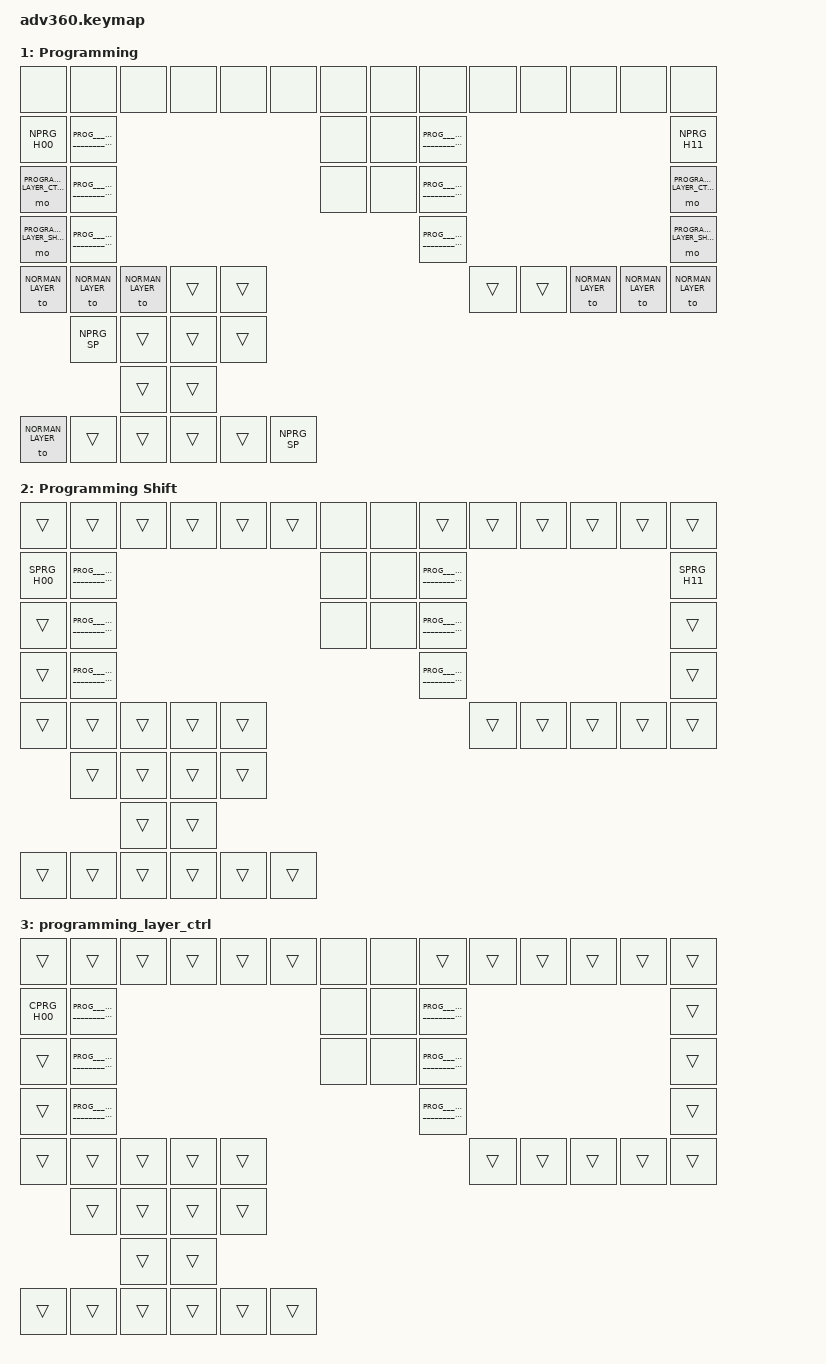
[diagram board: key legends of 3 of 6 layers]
#include <behaviors.dtsi>
#include <dt-bindings/zmk/keys.h>
#include <dt-bindings/zmk/bt.h>
#include <dt-bindings/zmk/rgb.h>
#include <dt-bindings/zmk/stp.h>
#include <dt-bindings/zmk/backlight.h>
#include <dt-bindings/zmk/pointing.h>

#define NORMAN_LAYER 0
#define PROGRAMMING_LAYER 1
#define PROGRAMMING_LAYER_SHIFT 2
#define PROGRAMMING_LAYER_CTRL 3
#define LOWER_LAYER 4
#define MOD_LAYER 5
#define GUI_LAYER 1

#define MO_MOD &mo MOD_LAYER

#define MO_LOWER &mo LOWER_LAYER
#define TOG_LOWER &tog LOWER_LAYER

// sticky-layer
&sl { release-after-ms = <999999>; };

// FIXME: shift+NPRG_CM should insert <, not activate the layer
#define NPRG_CM &sl PROGRAMMING_LAYER
#define MO_SPRG &mo PROGRAMMING_LAYER_SHIFT
#define MO_CPRG &mo PROGRAMMING_LAYER_CTRL
#define STCH_EX &to NORMAN_LAYER

#define ____________________NUMBERS__L___________________  &kp N1    &kp N2    &kp N3    &kp N4    &kp N5
#define ____________________NUMBERS__R___________________  &kp N6    &kp N7    &kp N8    &kp N9    &kp N0
#define ____________________QWERTY__L1___________________  &kp Q     &kp W     &kp E     &kp R     &kp T
#define ____________________QWERTY__L2___________________  &kp A     &kp S     &kp D     &kp F     &kp G
#define ____________________QWERTY__L3___________________  &kp Z     &kp X     &kp C     &kp V     &kp B
#define ____________________QWERTY__R1___________________  &kp Y     &kp U     &kp I     &kp O     &kp P
#define ____________________QWERTY__R2___________________  &kp H     &kp J     &kp K     &kp L     &kp SEMI
#define ____________________QWERTY__R3___________________  &kp N     &kp M     &kp COMMA &kp DOT   &kp FSLH
#define ____________________NORMAN__L1___________________  &kp Q     &kp W     &kp D     &kp F     &kp K
#define ____________________NORMAN__L2___________________  &kp A     &kp S     &kp E     &kp T     &kp G
#define ____________________NORMAN__L3___________________  &kp Z     &kp X     &kp C     &kp V     &kp B
#define ____________________NORMAN__R1___________________  &kp J     &kp U     &kp R     &kp L     &kp ESC
#define ____________________NORMAN__R2___________________  &kp Y     &kp N     &kp I     &kp O     &kp H
#define ____________________NORMAN__R3___________________  &kp P     &kp M     NPRG_CM   &kp DOT   &kp FSLH

#define ______________________________LOWER___L1___________________  &none     &kp LEFT     &kp DOWN     &kp UP       &kp RIGHT     &kp Z
#define ____________________LOWER___R1__________________________     &kp J     &kp HOME     &kp PGDN     &kp PGUP     &kp END       &kp DEL
#define ______________________________LOWER___L2___________________  &none     &kp HOME     &kp PGUP     &kp PGDN     &kp END       &none
#define ____________________LOWER___R2__________________________     &kp Z     &kp LEFT     &kp DOWN     &kp UP       &kp RIGHT     &none
#define ______________________________LOWER___L3___________________  &kp LSHFT &kp LG(LEFT) &kp LG(UP)   &kp LG(DOWN) &kp LG(RIGHT) &none
#define ____________________LOWER___R3__________________________     &kp P     &kp LA(LEFT) &kp LA(DOWN) &kp LA(UP)   &kp LA(RIGHT) &kp RSHFT

// https://github.com/rastasheep/zmk-config/commit/b8607d4beb15a29671cf7921a1fe5060a7740c6b
#define HYP LS(LC(LA(LGUI)))
#define HYPER(key) LS(LC(LA(LG(key))))

// GUI_L,   HYPER_L, KC_LALT, KC_LGUI,                   KC_RGUI, KC_RALT, HYPER_R, GUI_R,
// FIXME: use layer-tap &lt for this:
#define GUI_L &kp LBKT
// #define GUI_L &mt &mo GUI_LAYER LBKT
#define GUI_R &kp RBKT
// #define GUI_R &mt &mo GUI_LAYER RBKT
#define HYPER_L &mt HYP RBKT
#define HYPER_R &mt HYP LBKT

#define CTL_ESC &mt LCTRL ESC
#define CTL_ENT &mt RCTRL ENTER

// presumes Ctrl-E will go to end of line
#define GEND_LINE &kp LC(E)

// RGB LEDs: on top of the thumb clusters
#define RGBLED_TG &rgb_ug RGB_MEFS_CMD 5
#define BOOTLOADR &bootloader
#define BT_SEL_0  &bt BT_SEL 0
#define BT_SEL_1  &bt BT_SEL 1
#define BT_SEL_2  &bt BT_SEL 2
#define BT_SEL_3  &bt BT_SEL 3
#define BT_SEL_4  &bt BT_SEL 4
#define BT_CLR___ &bt BT_CLR

#define BL_INC___ &bl BL_INC
#define BL_DEC___ &bl BL_DEC
#define BL_TOG___ &bl BL_TOG
#define RGB_TOG__ &rgb_ug RGB_TOG

/ {
  behaviors {
    #include "macros.dtsi"
      #include "version.dtsi"

    ZMK_MACRO(NPRG_SP, bindings = <&kp COMMA  &kp SPACE    STCH_EX>;)

// use Mod-Morph to combine these to a single layer?  https://zmk.dev/docs/behaviors/mod-morph
//
//↘↩ │  %  │  &  │  ?  │  +  │  @     $  │  _  │  [  │  ]  │  !  │ ↘␣{↩
//─────┼─────┼─────┼─────┼─────┼───     ───┼─────┼─────┼─────┼─────┼─────
//     │  /  │  (  │  =  │  ;  │  {     }  │  :  │  *  │  )  │  -  │
//─────┼─────┼─────┼─────┼─────┼───     ───┼─────┼─────┼─────┼─────┼─────
//     │  ~  │  `  │  ^  │  "  │  |     \  │  ,  │  #  │  '  │     │
#define ____________________PROG____L1___________________  &kp PRCNT &kp AMPS  &kp QMARK &kp PLUS  &kp AT
#define ____________________PROG____L2___________________  &kp FSLH  &kp LPAR  &kp EQUAL &kp SEMI  &kp LBRC
#define ____________________PROG____L3___________________  &kp TILDE &kp GRAVE &kp CARET &kp DQT   &kp PIPE
#define ____________________PROG____R1___________________  &kp DLLR  &kp UNDER &kp LBKT  &kp RBKT  &kp EXCL
#define ____________________PROG____R2___________________  &kp RBRC  &kp COLON &kp STAR  &kp RPAR  &kp MINUS
#define ____________________PROG____R3___________________  &kp BSLH  &kp COMMA &kp HASH  &kp SQT   &none

    ZMK_MACRO(NPRG_H00, bindings = <GEND_LINE &kp ENTER STCH_EX>;)
    ZMK_MACRO(NPRG_H11, bindings = <GEND_LINE &kp SPACE &kp LBRC  &kp ENTER STCH_EX>;)

//          1     2     3     4     5      6    7     8     9     10
// H ↘;↩│     │ &&  │     │ +=  │ @q        │     │ []  │ ->  │ !=  │ ↘␣{
//   ─────┼─────┼─────┼─────┼─────┼───     ───┼─────┼─────┼─────┼─────┼─────
// M      │ /=  │ ()  │ ==  │     │ {}        │ ::  │     │     │ -=  │
//   ─────┼─────┼─────┼─────┼─────┼───     ───┼─────┼─────┼─────┼─────┼─────
// L      │     │     │     │     │ ||        │     │ <=  │ >=  │     │
#define ____________________PROG___SL1___________________  &none     &SPRG_H02 &none     &SPRG_H04 &SPRG_H05
#define ____________________PROG___SL2___________________  &SPRG_M01 &SPRG_M02 &SPRG_M03 &none     &SPRG_M05
#define ____________________PROG___SL3___________________  &none     &none     &none     &none     &SPRG_L05
#define ____________________PROG___SR1___________________  &none     &none     &SPRG_H08 &SPRG_H09 &SPRG_H10
#define ____________________PROG___SR2___________________  &none     &SPRG_M07 &none     &none     &SPRG_M10
#define ____________________PROG___SR3___________________  &none     &none     &SPRG_L08 &SPRG_L09 &none

    ZMK_MACRO(SPRG_H00, bindings = <GEND_LINE &kp SEMI  &kp ENTER STCH_EX>;)
    ZMK_MACRO(SPRG_H11, bindings = <GEND_LINE &kp SPACE &kp LBRC  STCH_EX>;)

    ZMK_MACRO(SPRG_H02, bindings = <&kp AMPS  &kp AMPS    STCH_EX>;)
    ZMK_MACRO(SPRG_H04, bindings = <&kp PLUS  &kp EQUAL   STCH_EX>;)
    ZMK_MACRO(SPRG_H05, bindings = <&kp AT    &kp Q       STCH_EX>;)
    ZMK_MACRO(SPRG_H08, bindings = <&kp LBKT  &kp RBKT    STCH_EX>;)
    ZMK_MACRO(SPRG_H09, bindings = <&kp MINUS &kp GT      STCH_EX>;)
    ZMK_MACRO(SPRG_H10, bindings = <&kp EXCL  &kp EQUAL   STCH_EX>;)

    ZMK_MACRO(SPRG_M01, bindings = <&kp FSLH  &kp EQUAL   STCH_EX>;)
    ZMK_MACRO(SPRG_M02, bindings = <&kp LPAR  &kp RPAR    STCH_EX>;)
    ZMK_MACRO(SPRG_M03, bindings = <&kp EQUAL &kp EQUAL   STCH_EX>;)
    ZMK_MACRO(SPRG_M05, bindings = <&kp LBRC  &kp RBRC    STCH_EX>;)
    ZMK_MACRO(SPRG_M07, bindings = <&kp COLON &kp COLON   STCH_EX>;)
    ZMK_MACRO(SPRG_M10, bindings = <&kp MINUS &kp EQUAL   STCH_EX>;)

    ZMK_MACRO(SPRG_L05, bindings = <&kp PIPE  &kp PIPE    STCH_EX>;)
    ZMK_MACRO(SPRG_L08, bindings = <&kp LT    &kp EQUAL   STCH_EX>;)
    ZMK_MACRO(SPRG_L09, bindings = <&kp GT    &kp EQUAL   STCH_EX>;)

//          1     2     3     4     5      6    7     8     9     10
// H ↘:↩│     │     │     │ ++  │ @@        │     │     │     │     │
//   ─────┼─────┼─────┼─────┼─────┼───     ───┼─────┼─────┼─────┼─────┼─────
// M      │     │     │ =>  │     │           │ :=  │     │     │ --  │
//   ─────┼─────┼─────┼─────┼─────┼───     ───┼─────┼─────┼─────┼─────┼─────
// L      │     │     │     │     │           │     │     │     │     │
#define ____________________PROG___CL1___________________  &none     &none     &none     &CPRG_H04 &CPRG_H05
#define ____________________PROG___CL2___________________  &none     &none     &CPRG_M03 &none     &none
#define ____________________PROG___CL3___________________  &none     &none     &none     &none     &none
#define ____________________PROG___CR1___________________  &none     &none     &none     &none     &none
#define ____________________PROG___CR2___________________  &none     &CPRG_M07 &none     &none     &CPRG_M10
#define ____________________PROG___CR3___________________  &none     &none     &none     &none     &none

    ZMK_MACRO(CPRG_H00, bindings = <GEND_LINE &kp COLON &kp ENTER STCH_EX>;)

    ZMK_MACRO(CPRG_H04, bindings = <&kp PLUS  &kp PLUS    STCH_EX>;)
    ZMK_MACRO(CPRG_H05, bindings = <&kp AT    &kp AT      STCH_EX>;)

    ZMK_MACRO(CPRG_M03, bindings = <&kp EQUAL &kp GT      STCH_EX>;)
    ZMK_MACRO(CPRG_M07, bindings = <&kp COLON &kp EQUAL   STCH_EX>;)
    ZMK_MACRO(CPRG_M10, bindings = <&kp MINUS &kp MINUS   STCH_EX>;)

    hm: homerow_mods {
      compatible = "zmk,behavior-hold-tap";
      label = "HOMEROW_MODS";
      #binding-cells = <2>;
      tapping-term-ms = <200>;
      quick_tap_ms = <175>;
      flavor = "tap-preferred";
      bindings = <&kp>, <&kp>;
    };
  };

  keymap {
    compatible = "zmk,keymap";

    // 0
    default_layer {
      //_________ _________ _________ _________ _________ _________ _________   _________ _________ _________ _________ _________ _________ _________
      display-name = "Base";
      bindings = <
        &kp EQUAL ____________________NUMBERS__L___________________ MO_MOD      MO_MOD    ____________________NUMBERS__R___________________ &kp MINUS
        &kp TAB   ____________________NORMAN__L1___________________ &none       &none     ____________________NORMAN__R1___________________ &kp BSLH
        CTL_ESC   ____________________NORMAN__L2___________________ &none       &none     ____________________NORMAN__R2___________________ CTL_ENT
        &kp LSHFT ____________________NORMAN__L3___________________                       ____________________NORMAN__R3___________________ &kp RSHFT
        NPRG_CM   GUI_L     HYPER_L   &kp LALT  &kp LGUI                                            &kp RGUI  &kp RALT  HYPER_R   GUI_R     NPRG_CM

                  &kp SPACE &kp CAPS  &kp CAPS  &kp ESC
                            &none     &none
        MO_LOWER  &kp BSPC  &none     TOG_LOWER &kp ENTER &kp SPACE
      >;
    };
    // 1
    programming_layer {
      //_________ _________ _________ _________ _________ _________ _________   _________ _________ _________ _________ _________ _________ _________
      display-name = "Programming";
      bindings = <
        &none     &none     &none     &none     &none     &none     &none       &none     &none     &none      &none     &none     &none    &none
        &NPRG_H00 ____________________PROG____L1___________________ &none       &none     ____________________PROG____R1___________________ &NPRG_H11
        MO_CPRG   ____________________PROG____L2___________________ &none       &none     ____________________PROG____R2___________________ MO_CPRG
        MO_SPRG   ____________________PROG____L3___________________                       ____________________PROG____R3___________________ MO_SPRG
        STCH_EX   STCH_EX   STCH_EX   &trans    &trans                                              &trans     &trans    STCH_EX   STCH_EX  STCH_EX

                  &NPRG_SP  &trans    &trans    &trans
                            &trans    &trans
        STCH_EX   &trans    &trans    &trans    &trans   &NPRG_SP
      >;
    };
    // 2
    programming_layer_shift {
      //_________ _________ _________ _________ _________ _________ _________   _________ _________ _________ _________ _________ _________ _________
      display-name = "Programming Shift";
      bindings = <
        &trans    &trans    &trans    &trans    &trans    &trans    &none       &none     &trans    &trans    &trans    &trans    &trans    &trans
        &SPRG_H00 ____________________PROG___SL1___________________ &none       &none     ____________________PROG___SR1___________________ &SPRG_H11
        &trans    ____________________PROG___SL2___________________ &none       &none     ____________________PROG___SR2___________________ &trans
        &trans    ____________________PROG___SL3___________________                       ____________________PROG___SR3___________________ &trans
        &trans    &trans    &trans    &trans    &trans                                              &trans    &trans    &trans    &trans    &trans

                  &trans    &trans    &trans    &trans
                            &trans    &trans
        &trans    &trans    &trans    &trans    &trans    &trans
      >;
    };
    // 3
    programming_layer_ctrl {
      //_________ _________ _________ _________ _________ _________ _________   _________ _________ _________ _________ _________ _________ _________
      bindings = <
        &trans    &trans    &trans    &trans    &trans    &trans    &none       &none     &trans    &trans    &trans    &trans    &trans    &trans
        &CPRG_H00 ____________________PROG___CL1___________________ &none       &none     ____________________PROG___CR1___________________ &trans
        &trans    ____________________PROG___CL2___________________ &none       &none     ____________________PROG___CR2___________________ &trans
        &trans    ____________________PROG___CL3___________________                       ____________________PROG___CR3___________________ &trans
        &trans    &trans    &trans    &trans    &trans                                              &trans    &trans    &trans    &trans    &trans

                  &trans    &trans    &trans    &trans
                            &trans    &trans
        &trans    &trans    &trans    &trans    &trans    &trans
      >;
    };
    // 4
    lower {
      //_________ _________ _________ _________ _________ _________ _________   _________ _________ _________ _________ _________ _________ _________
      bindings = <
        &trans    &trans    &trans    &trans    &trans    &trans    &none       &none     &trans    &trans    &trans    &trans    &trans    &trans
        ______________________________LOWER___L1___________________ &none       &none     ____________________LOWER___R1__________________________
        ______________________________LOWER___L2___________________ &none       &none     ____________________LOWER___R2__________________________
        ______________________________LOWER___L3___________________                       ____________________LOWER___R3__________________________
        &trans    &trans    &trans    &trans    &trans                                              &trans    &trans    &trans    &trans    &trans

                  &trans    &trans    &trans    &trans
                            &trans    &trans
        &trans    &trans    &trans    &trans    &trans    &kp LA(BSPC)
      >;
    };
    // 5
    mod {
      //_________ _________ _________ _________ _________ _________ _________   _________ _________ _________ _________ _________ _________ _________
      display-name = "Mod";
      bindings = <
        &none     BT_SEL_0  BT_SEL_1  BT_SEL_2  BT_SEL_3  BT_SEL_4  &trans      &trans    &none     &none     &none     &none     &none     &none
        &none     &none     &none     &none     &none     &none     BOOTLOADR   BOOTLOADR &none     &none     &none     &none     &none     &none
        &none     &none     &none     &none     &none     &none     &none       RGBLED_TG &none     &none     &none     &none     &none     &none
        &none     &none     &none     &none     &none     &none                           &none     &none     &none     &none     &none     &none
        &none     &none     &none     &none     &none                                               BL_INC___ BL_DEC___ &none     &none     &none

                  &none     &none     BT_CLR___ &none
                            &none     &none
        &none     &none     &none     &none     BL_TOG___ RGB_TOG__
      >;
    };
    extra1 {
      display-name = "Red";
      status = "reserved";
    };

    extra2 {
      display-name = "Purple";
      status = "reserved";
    };

    extra3 {
      display-name = "Cyan";
      status = "reserved";
    };

    extra4 {
      display-name = "Yellow";
      status = "reserved";
    };
  };
};
